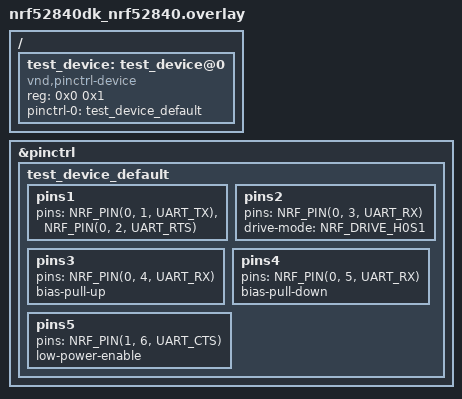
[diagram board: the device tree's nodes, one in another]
/*
 * Copyright (c) 2021 Nordic Semiconductor ASA
 *
 * SPDX-License-Identifier: Apache-2.0
 */

/ {
	test_device: test_device@0 {
		compatible = "vnd,pinctrl-device";
		reg = <0x0 0x1>;
		pinctrl-0 = <&test_device_default>;
		pinctrl-names = "default";
	};
};

&pinctrl {
	test_device_default: test_device_default {
		/* Note: the groups are just meant for testing if properties and
		   pins are parsed correctly, but do not necessarily represent a
		   feasible combination */
		pins1 {
			pins = <NRF_PIN(0, 1, UART_TX)>,
			       <NRF_PIN(0, 2, UART_RTS)>;
		};
		pins2 {
			pins = <NRF_PIN(0, 3, UART_RX)>;
			drive-mode = <NRF_DRIVE_H0S1>;
		};
		pins3 {
			pins = <NRF_PIN(0, 4, UART_RX)>;
			bias-pull-up;
		};
		pins4 {
			pins = <NRF_PIN(0, 5, UART_RX)>;
			bias-pull-down;
		};
		pins5 {
			pins = <NRF_PIN(1, 6, UART_CTS)>;
			low-power-enable;
		};
	};
};
